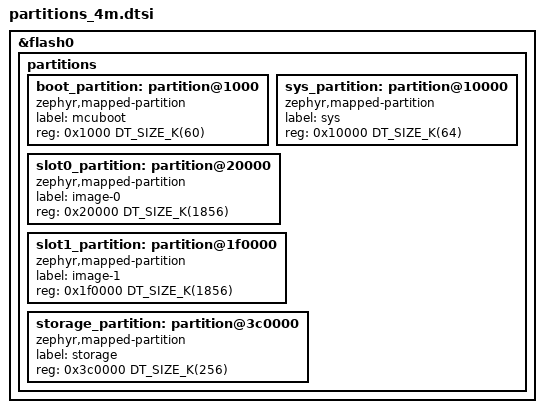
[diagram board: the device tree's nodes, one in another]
/*
 * SPDX-License-Identifier: Apache-2.0
 *
 * Shared flash partition layout for ESP32-DevKitC with MCUboot (4 MB).
 *
 * Included by both the board overlay (my_app image) and the sysbuild
 * mcuboot overlay so both images agree on flash geometry.
 *
 * Removes unused vendor AMP partitions (APPCPU, LPCORE, scratch,
 * coredump) and defines only what a single PROCPU image needs.
 */

/* ── Remove vendor AMP slots ──────────────────────────────────────── */

/delete-node/ &boot_partition;
/delete-node/ &sys_partition;
/delete-node/ &slot0_partition;
/delete-node/ &slot1_partition;
/delete-node/ &slot0_appcpu_partition;
/delete-node/ &slot1_appcpu_partition;
/delete-node/ &slot0_lpcore_partition;
/delete-node/ &slot1_lpcore_partition;
/delete-node/ &storage_partition;
/delete-node/ &scratch_partition;
/delete-node/ &coredump_partition;

/* ── Custom layout (4 MB flash) ─────────────────────────────────────
 *
 *   0x001000 ─ 0x010000   mcuboot           ( 60 KB)
 *   0x010000 ─ 0x020000   sys (PHY calib)   ( 64 KB) ← WiFi needs this
 *   0x020000 ─ 0x1F0000   image-0 / slot0   (1856 KB)
 *   0x1F0000 ─ 0x3C0000   image-1 / slot1   (1856 KB)
 *   0x3C0000 ─ 0x400000   storage           ( 256 KB)
 */

&flash0 {
	partitions {
		ranges;
		#address-cells = <1>;
		#size-cells = <1>;

		boot_partition: partition@1000 {
			compatible = "zephyr,mapped-partition";
			label = "mcuboot";
			reg = <0x1000 DT_SIZE_K(60)>;
		};

		sys_partition: partition@10000 {
			compatible = "zephyr,mapped-partition";
			label = "sys";
			reg = <0x10000 DT_SIZE_K(64)>;
		};

		slot0_partition: partition@20000 {
			compatible = "zephyr,mapped-partition";
			label = "image-0";
			reg = <0x20000 DT_SIZE_K(1856)>;
		};

		slot1_partition: partition@1f0000 {
			compatible = "zephyr,mapped-partition";
			label = "image-1";
			reg = <0x1f0000 DT_SIZE_K(1856)>;
		};

		storage_partition: partition@3c0000 {
			compatible = "zephyr,mapped-partition";
			label = "storage";
			reg = <0x3c0000 DT_SIZE_K(256)>;
		};
	};
};
